AUTOSAR XML (schema 4.0)
package /ApplicationSwcs
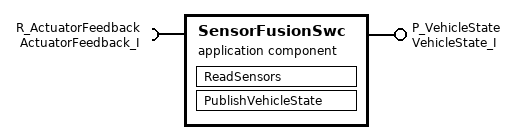
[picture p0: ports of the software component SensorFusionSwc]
  application sw component type SensorFusionSwc
    provide port P_VehicleState: provided-interface=VehicleState_I
    require port R_ActuatorFeedback: required-interface=ActuatorFeedback_I
    behavior SensorFusionSwc_IB
      runnable ReadSensors
      runnable PublishVehicleState
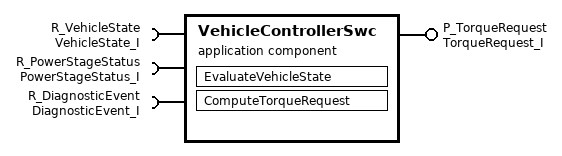
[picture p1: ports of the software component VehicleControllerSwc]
  application sw component type VehicleControllerSwc
    require port R_VehicleState: required-interface=VehicleState_I
    require port R_PowerStageStatus: required-interface=PowerStageStatus_I
    require port R_DiagnosticEvent: required-interface=DiagnosticEvent_I
    provide port P_TorqueRequest: provided-interface=TorqueRequest_I
    behavior VehicleControllerSwc_IB
      runnable EvaluateVehicleState
      runnable ComputeTorqueRequest
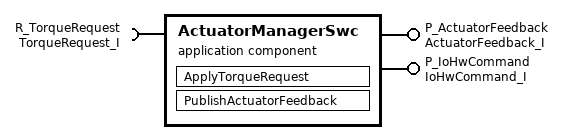
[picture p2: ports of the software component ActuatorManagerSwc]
  application sw component type ActuatorManagerSwc
    require port R_TorqueRequest: required-interface=TorqueRequest_I
    provide port P_ActuatorFeedback: provided-interface=ActuatorFeedback_I
    provide port P_IoHwCommand: provided-interface=IoHwCommand_I
    behavior ActuatorManagerSwc_IB
      runnable ApplyTorqueRequest
      runnable PublishActuatorFeedback
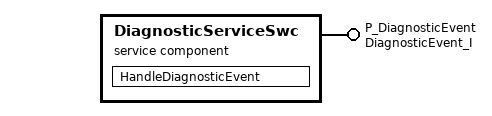
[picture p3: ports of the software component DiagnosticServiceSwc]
  service sw component type DiagnosticServiceSwc
    provide port P_DiagnosticEvent: provided-interface=DiagnosticEvent_I
    behavior DiagnosticServiceSwc_IB
      runnable HandleDiagnosticEvent
